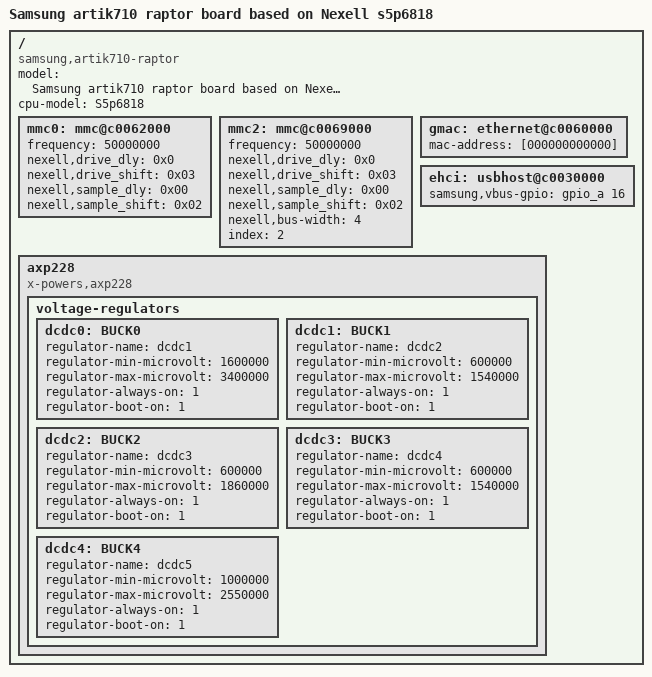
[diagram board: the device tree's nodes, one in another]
/*
 * (C) Copyright 2016 Nexell
 * Hyunseok, Jung <hsjung@nexell.co.kr>
 *
 * SPDX-License-Identifier: GPL-2.0+
 */

/dts-v1/;
#include "s5p6818-artik710.dtsi"

/ {
	model = "Samsung artik710 raptor board based on Nexell s5p6818";
	cpu-model = "S5p6818";

	compatible = "samsung,artik710-raptor", "samsung,artik710",
		   "nexell,s5p6818";

	mmc0:mmc@c0062000 {
		frequency = <50000000>;
		nexell,drive_dly = <0x0>;
		nexell,drive_shift = <0x03>;
		nexell,sample_dly = <0x00>;
		nexell,sample_shift = <0x02>;
		status = "okay";
	};

	mmc2:mmc@c0069000 {
		frequency = <50000000>;
		nexell,drive_dly = <0x0>;
		nexell,drive_shift = <0x03>;
		nexell,sample_dly = <0x00>;
		nexell,sample_shift = <0x02>;
		nexell,bus-width = <4>;
		index = <2>;
		status = "okay";
	};

	gmac:ethernet@c0060000 {
		mac-address = [000000000000]; /* Filled in by U-Boot */
		status = "okay";
	};

	ehci:usbhost@c0030000 {
		samsung,vbus-gpio = <&gpio_a 16 0>;
		status = "okay";
	};

	axp228 {
        compatible = "x-powers,axp228";

   	voltage-regulators {
		dcdc0: BUCK0 {
			regulator-name = "dcdc1";
			regulator-min-microvolt = <1600000>;
			regulator-max-microvolt = <3400000>;
			regulator-always-on = <1>;
			regulator-boot-on = <1>;
		};

		dcdc1: BUCK1 {
			regulator-name = "dcdc2";
			regulator-min-microvolt = <600000>;
			regulator-max-microvolt = <1540000>;
			regulator-always-on = <1>;
			regulator-boot-on = <1>;
		};

		dcdc2: BUCK2 {
			regulator-name = "dcdc3";
			regulator-min-microvolt = <600000>;
			regulator-max-microvolt = <1860000>;
			regulator-always-on = <1>;
			regulator-boot-on = <1>;
		};

		dcdc3: BUCK3 {
			regulator-name = "dcdc4";
			regulator-min-microvolt = <600000>;
			regulator-max-microvolt = <1540000>;
			regulator-always-on = <1>;
			regulator-boot-on = <1>;
		};

		dcdc4: BUCK4 {
			regulator-name = "dcdc5";
			regulator-min-microvolt = <1000000>;
			regulator-max-microvolt = <2550000>;
			regulator-always-on = <1>;
			regulator-boot-on = <1>;
		};
	}; /* voltage-regulators */
	};
};

